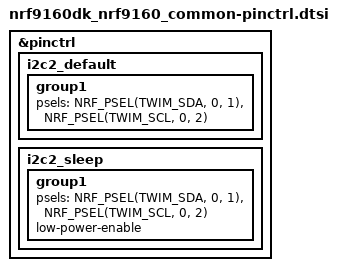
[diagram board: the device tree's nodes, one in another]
/*
 * Copyright (c) 2022 Nordic Semiconductor
 * SPDX-License-Identifier: Apache-2.0
 */

&pinctrl {
	i2c2_default: i2c2_default {
		group1 {
			psels = <NRF_PSEL(TWIM_SDA, 0, 1)>,
				<NRF_PSEL(TWIM_SCL, 0, 2)>;
		};
	};

	i2c2_sleep: i2c2_sleep {
		group1 {
			psels = <NRF_PSEL(TWIM_SDA, 0, 1)>,
				<NRF_PSEL(TWIM_SCL, 0, 2)>;
			low-power-enable;
		};
	};

};
